# STM32F411CCU6 register map
File version: 1.0
Registers are 32-bit, access not given, reset 0x0 unless marked. A register's access mark holds for its fields unless they carry their own. Offsets are from the block's base; [hi:lo] are bit positions; {n}, {i} and the like mark numbered series; 'fields as' and 'values as' point back to an identical list.

## USB_OTG_FS
Base 0x50000000
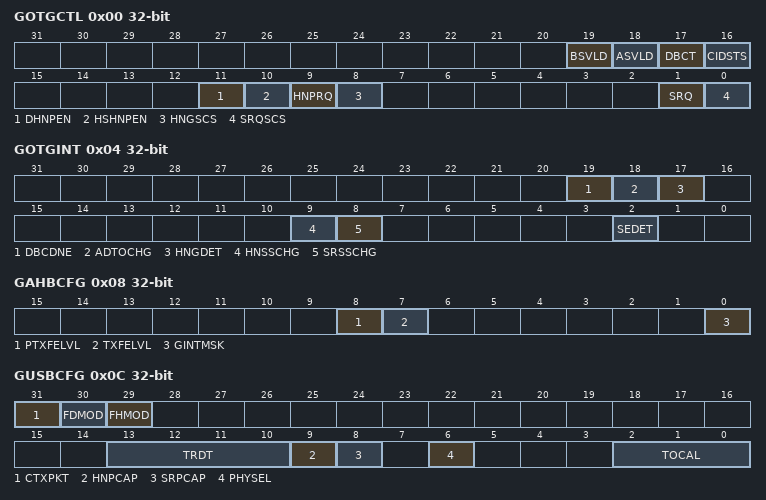
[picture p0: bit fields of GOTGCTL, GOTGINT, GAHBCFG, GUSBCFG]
0x00 GOTGCTL
  [19] BSVLD, [18] ASVLD, [17] DBCT, [16] CIDSTS, [11] DHNPEN, [10] HSHNPEN, [9] HNPRQ, [8] HNGSCS, [1] SRQ, [0] SRQSCS
0x04 GOTGINT
  [19] DBCDNE, [18] ADTOCHG, [17] HNGDET, [9] HNSSCHG, [8] SRSSCHG, [2] SEDET
0x08 GAHBCFG
  [8] PTXFELVL, [7] TXFELVL, [0] GINTMSK
0x0C GUSBCFG
  [31] CTXPKT, [30] FDMOD, [29] FHMOD, [13:10] TRDT, [9] HNPCAP, [8] SRPCAP, [6] PHYSEL, [2:0] TOCAL
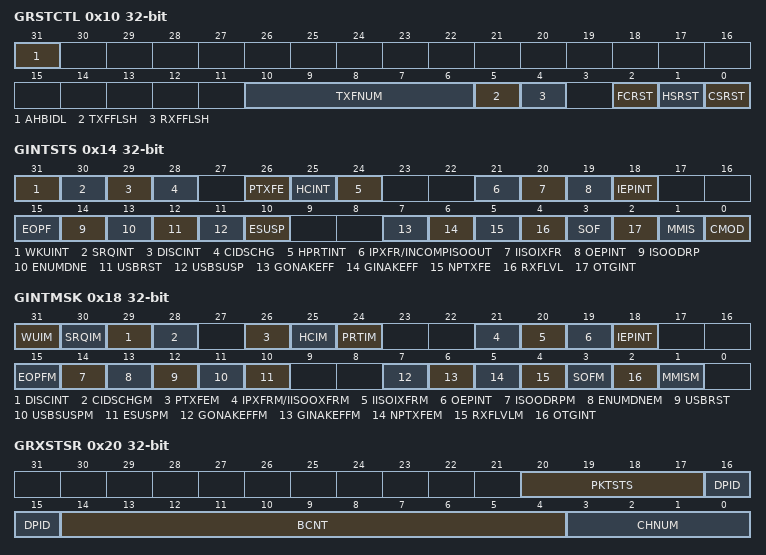
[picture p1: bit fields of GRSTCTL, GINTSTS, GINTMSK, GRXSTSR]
0x10 GRSTCTL
  [31] AHBIDL, [10:6] TXFNUM, [5] TXFFLSH, [4] RXFFLSH, [2] FCRST, [1] HSRST, [0] CSRST
0x14 GINTSTS
  [31] WKUINT, [30] SRQINT, [29] DISCINT, [28] CIDSCHG, [26] PTXFE, [25] HCINT, [24] HPRTINT, [21] IPXFR/INCOMPISOOUT, [20] IISOIXFR, [19] OEPINT, [18] IEPINT, [15] EOPF, [14] ISOODRP, [13] ENUMDNE, [12] USBRST, [11] USBSUSP, [10] ESUSP, [7] GONAKEFF, [6] GINAKEFF, [5] NPTXFE, [4] RXFLVL, [3] SOF, [2] OTGINT, [1] MMIS, [0] CMOD
0x18 GINTMSK
  [31] WUIM, [30] SRQIM, [29] DISCINT, [28] CIDSCHGM, [26] PTXFEM, [25] HCIM, [24] PRTIM, [21] IPXFRM/IISOOXFRM, [20] IISOIXFRM, [19] OEPINT, [18] IEPINT, [15] EOPFM, [14] ISOODRPM, [13] ENUMDNEM, [12] USBRST, [11] USBSUSPM, [10] ESUSPM, [7] GONAKEFFM, [6] GINAKEFFM, [5] NPTXFEM, [4] RXFLVLM, [3] SOFM, [2] OTGINT, [1] MMISM
0x20 GRXSTSR
  [20:17] PKTSTS, [16:15] DPID, [14:4] BCNT, [3:0] CHNUM
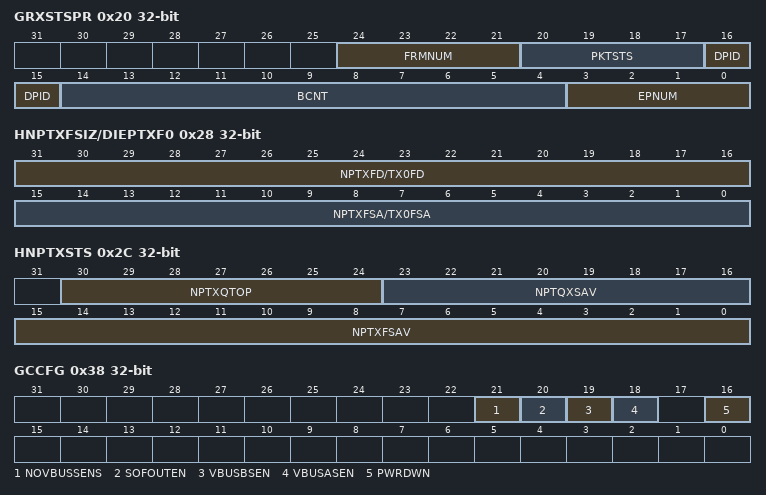
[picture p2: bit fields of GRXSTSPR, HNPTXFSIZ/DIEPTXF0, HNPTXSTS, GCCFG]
0x20 GRXSTSPR
  [24:21] FRMNUM, [20:17] PKTSTS, [16:15] DPID, [14:4] BCNT, [3:0] EPNUM
0x24 GRXFSIZ
  [15:0] RXFD
0x28 HNPTXFSIZ/DIEPTXF0
  [31:16] NPTXFD/TX0FD, [15:0] NPTXFSA/TX0FSA
0x2C HNPTXSTS
  [30:24] NPTXQTOP, [23:16] NPTQXSAV, [15:0] NPTXFSAV
0x38 GCCFG
  [21] NOVBUSSENS, [20] SOFOUTEN, [19] VBUSBSEN, [18] VBUSASEN, [16] PWRDWN
0x3C CID
  [31:0] PRODUCT_ID
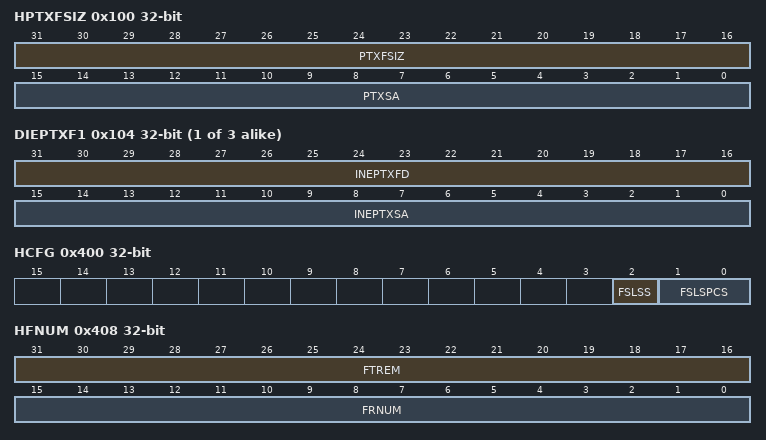
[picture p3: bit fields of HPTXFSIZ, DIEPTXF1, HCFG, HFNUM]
0x100 HPTXFSIZ
  [31:16] PTXFSIZ, [15:0] PTXSA
{0x100+4i} DIEPTXF{i} (i=1..3)
  [31:16] INEPTXFD, [15:0] INEPTXSA
0x400 HCFG
  [2] FSLSS, [1:0] FSLSPCS
0x404 HFIR
  [15:0] FRIVL
0x408 HFNUM
  [31:16] FTREM, [15:0] FRNUM
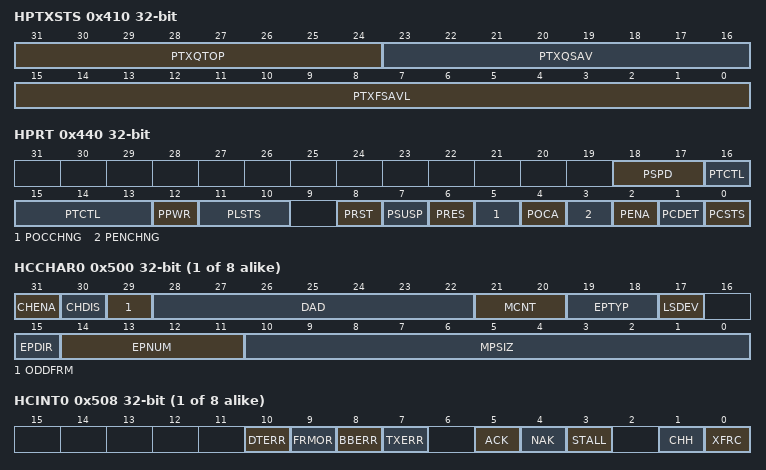
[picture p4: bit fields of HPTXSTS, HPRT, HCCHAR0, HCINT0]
0x410 HPTXSTS
  [31:24] PTXQTOP, [23:16] PTXQSAV, [15:0] PTXFSAVL
0x414 HAINT
  [15:0] HAINT
0x418 HAINTMSK
  [15:0] HAINTM
0x440 HPRT
  [18:17] PSPD, [16:13] PTCTL, [12] PPWR, [11:10] PLSTS, [8] PRST, [7] PSUSP, [6] PRES, [5] POCCHNG, [4] POCA, [3] PENCHNG, [2] PENA, [1] PCDET, [0] PCSTS
{0x500+0x20*i} HCCHAR{i} (i=0..7)
  [31] CHENA, [30] CHDIS, [29] ODDFRM, [28:22] DAD, [21:20] MCNT, [19:18] EPTYP, [17] LSDEV, [15] EPDIR, [14:11] EPNUM, [10:0] MPSIZ
{0x508+0x20*i} HCINT{i} (i=0..7)
  [10] DTERR, [9] FRMOR, [8] BBERR, [7] TXERR, [5] ACK, [4] NAK, [3] STALL, [1] CHH, [0] XFRC
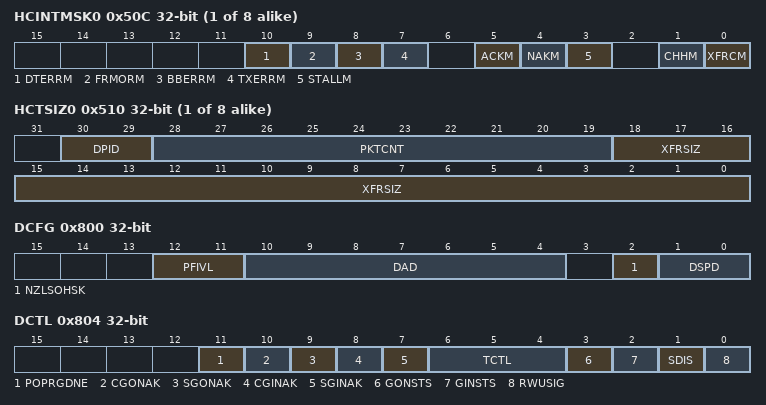
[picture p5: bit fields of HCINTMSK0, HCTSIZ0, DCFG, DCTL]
{0x50C+0x20*i} HCINTMSK{i} (i=0..7)
  [10] DTERRM, [9] FRMORM, [8] BBERRM, [7] TXERRM, [5] ACKM, [4] NAKM, [3] STALLM, [1] CHHM, [0] XFRCM
{0x510+0x20*i} HCTSIZ{i} (i=0..7)
  [30:29] DPID, [28:19] PKTCNT, [18:0] XFRSIZ
0x800 DCFG
  [12:11] PFIVL, [10:4] DAD, [2] NZLSOHSK, [1:0] DSPD
0x804 DCTL
  [11] POPRGDNE, [10] CGONAK, [9] SGONAK, [8] CGINAK, [7] SGINAK, [6:4] TCTL, [3] GONSTS, [2] GINSTS, [1] SDIS, [0] RWUSIG
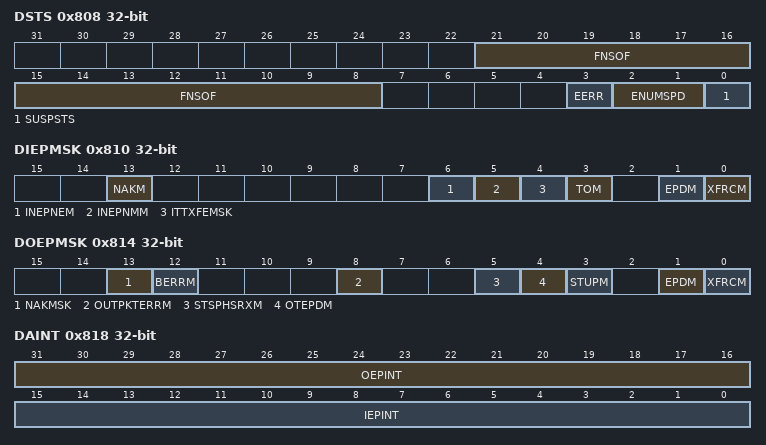
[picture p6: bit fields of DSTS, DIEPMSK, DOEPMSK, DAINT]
0x808 DSTS
  [21:8] FNSOF, [3] EERR, [2:1] ENUMSPD, [0] SUSPSTS
0x810 DIEPMSK
  [13] NAKM, [6] INEPNEM, [5] INEPNMM, [4] ITTXFEMSK, [3] TOM, [1] EPDM, [0] XFRCM
0x814 DOEPMSK
  [13] NAKMSK, [12] BERRM, [8] OUTPKTERRM, [5] STSPHSRXM, [4] OTEPDM, [3] STUPM, [1] EPDM, [0] XFRCM
0x818 DAINT
  [31:16] OEPINT, [15:0] IEPINT
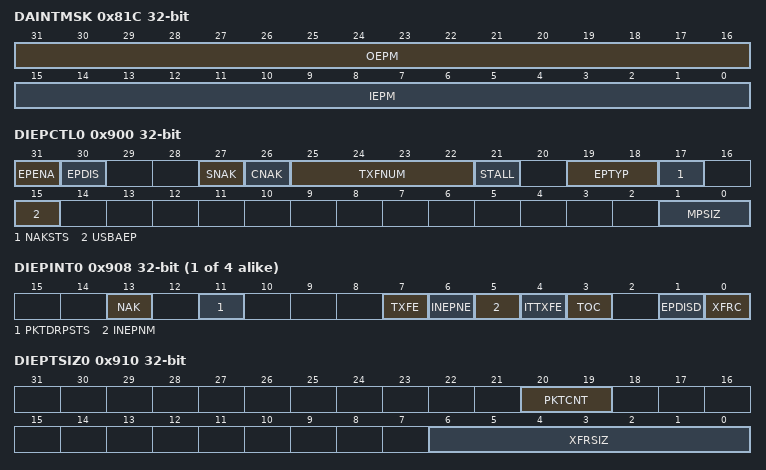
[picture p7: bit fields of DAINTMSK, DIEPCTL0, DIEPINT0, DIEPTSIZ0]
0x81C DAINTMSK
  [31:16] OEPM, [15:0] IEPM
0x828 DVBUSDIS
  [15:0] VBUSDT
0x82C DVBUSPULSE
  [11:0] DVBUSP
0x834 DIEPEMPMSK
  [15:0] INEPTXFEM
0x900 DIEPCTL0
  [31] EPENA, [30] EPDIS, [27] SNAK, [26] CNAK, [25:22] TXFNUM, [21] STALL, [19:18] EPTYP, [17] NAKSTS, [15] USBAEP, [1:0] MPSIZ
{0x908+0x20*i} DIEPINT{i} (i=0..3)
  [13] NAK, [11] PKTDRPSTS, [7] TXFE, [6] INEPNE, [5] INEPNM, [4] ITTXFE, [3] TOC, [1] EPDISD, [0] XFRC
0x910 DIEPTSIZ0
  [20:19] PKTCNT, [6:0] XFRSIZ
{0x918+0x20*i} DTXFSTS{i} (i=0..3)
  [15:0] INEPTFSAV
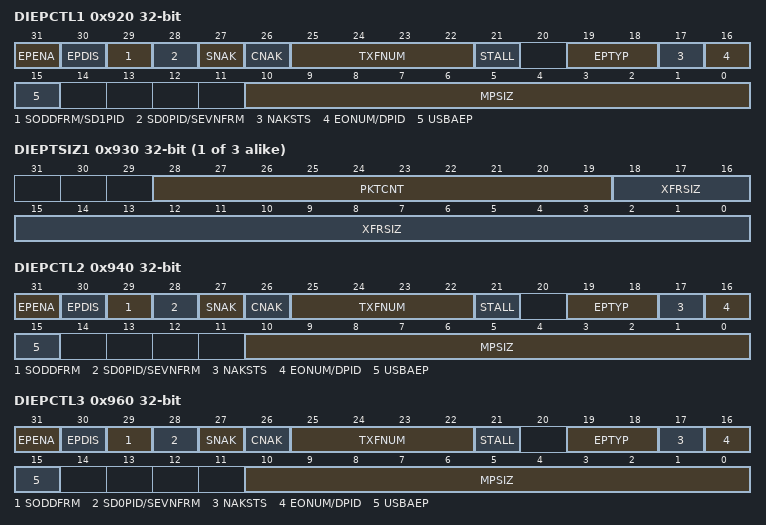
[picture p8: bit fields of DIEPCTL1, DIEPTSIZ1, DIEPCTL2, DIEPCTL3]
0x920 DIEPCTL1
  [31] EPENA, [30] EPDIS, [29] SODDFRM/SD1PID, [28] SD0PID/SEVNFRM, [27] SNAK, [26] CNAK, [25:22] TXFNUM, [21] STALL, [19:18] EPTYP, [17] NAKSTS, [16] EONUM/DPID, [15] USBAEP, [10:0] MPSIZ
{0x910+0x20*i} DIEPTSIZ{i} (i=1..3)
  [28:19] PKTCNT, [18:0] XFRSIZ
0x940 DIEPCTL2
  [31] EPENA, [30] EPDIS, [29] SODDFRM, [28] SD0PID/SEVNFRM, [27] SNAK, [26] CNAK, [25:22] TXFNUM, [21] STALL, [19:18] EPTYP, [17] NAKSTS, [16] EONUM/DPID, [15] USBAEP, [10:0] MPSIZ
0x960 DIEPCTL3
  fields as DIEPCTL2
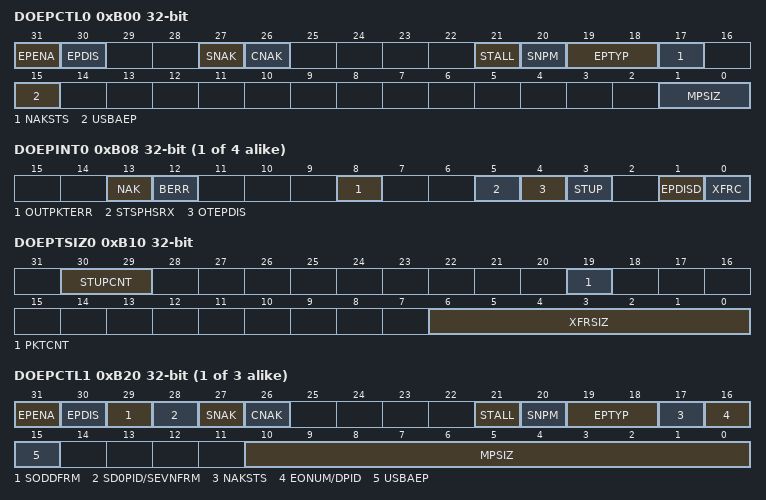
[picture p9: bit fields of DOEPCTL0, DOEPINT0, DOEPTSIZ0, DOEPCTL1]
0xB00 DOEPCTL0
  [31] EPENA, [30] EPDIS, [27] SNAK, [26] CNAK, [21] STALL, [20] SNPM, [19:18] EPTYP, [17] NAKSTS, [15] USBAEP, [1:0] MPSIZ
{0xB08+0x20*i} DOEPINT{i} (i=0..3)
  [13] NAK, [12] BERR, [8] OUTPKTERR, [5] STSPHSRX, [4] OTEPDIS, [3] STUP, [1] EPDISD, [0] XFRC
0xB10 DOEPTSIZ0
  [30:29] STUPCNT, [19] PKTCNT, [6:0] XFRSIZ
{0xB00+0x20*i} DOEPCTL{i} (i=1..3)
  [31] EPENA, [30] EPDIS, [29] SODDFRM, [28] SD0PID/SEVNFRM, [27] SNAK, [26] CNAK, [21] STALL, [20] SNPM, [19:18] EPTYP, [17] NAKSTS, [16] EONUM/DPID, [15] USBAEP, [10:0] MPSIZ
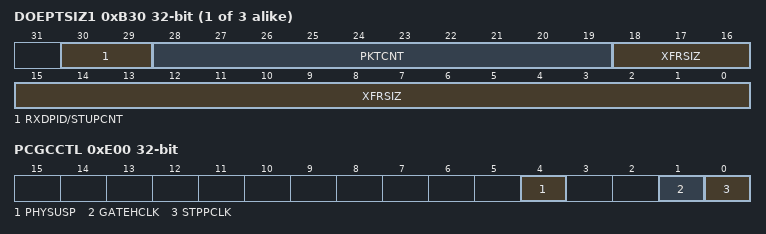
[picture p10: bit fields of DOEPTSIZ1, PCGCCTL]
{0xB10+0x20*i} DOEPTSIZ{i} (i=1..3)
  [30:29] RXDPID/STUPCNT, [28:19] PKTCNT, [18:0] XFRSIZ
0xE00 PCGCCTL
  [4] PHYSUSP, [1] GATEHCLK, [0] STPPCLK
